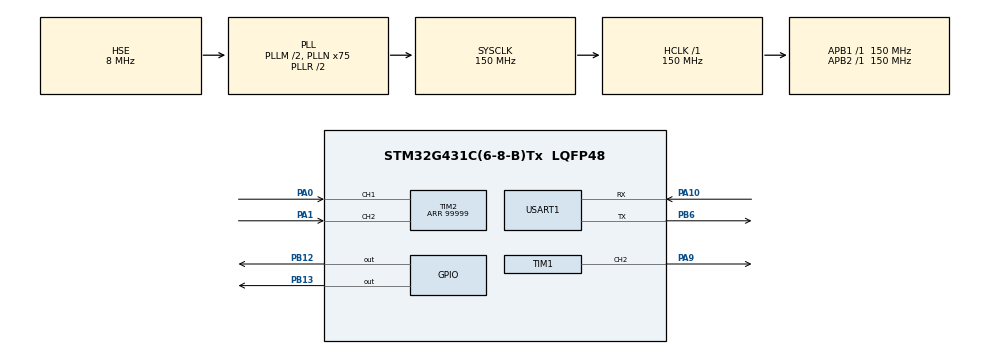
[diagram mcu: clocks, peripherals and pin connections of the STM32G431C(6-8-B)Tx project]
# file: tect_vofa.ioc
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Dma.Request0=USART1_TX
Dma.USART1_TX.0.Direction=DMA_MEMORY_TO_PERIPH
Dma.USART1_TX.0.EventEnable=DISABLE
Dma.USART1_TX.0.Instance=DMA1_Channel1
Dma.USART1_TX.0.MemDataAlignment=DMA_MDATAALIGN_BYTE
Dma.USART1_TX.0.MemInc=DMA_MINC_ENABLE
Dma.USART1_TX.0.Mode=DMA_NORMAL
Dma.USART1_TX.0.PeriphDataAlignment=DMA_PDATAALIGN_BYTE
Dma.USART1_TX.0.PeriphInc=DMA_PINC_DISABLE
Dma.USART1_TX.0.Polarity=HAL_DMAMUX_REQ_GEN_RISING
Dma.USART1_TX.0.Priority=DMA_PRIORITY_LOW
Dma.USART1_TX.0.RequestNumber=1
Dma.USART1_TX.0.SignalID=NONE
Dma.USART1_TX.0.SyncEnable=DISABLE
Dma.USART1_TX.0.SyncPolarity=HAL_DMAMUX_SYNC_NO_EVENT
Dma.USART1_TX.0.SyncRequestNumber=1
Dma.USART1_TX.0.SyncSignalID=NONE
Mcu.Family=STM32G4
Mcu.Name=STM32G431C(6-8-B)Tx
Mcu.Package=LQFP48
NVIC.DMA1_Channel1_IRQn=true\:0\:0\:false\:false\:true\:false\:true\:true
NVIC.PriorityGroup=NVIC_PRIORITYGROUP_4
NVIC.TIM6_DAC_IRQn=true\:9\:0\:true\:false\:true\:true\:true\:true
NVIC.TIM7_IRQn=true\:8\:0\:true\:false\:true\:true\:true\:true
NVIC.USART1_IRQn=true\:10\:0\:true\:false\:true\:false\:true\:true
PA0.Signal=S_TIM2_CH1
PA1.Signal=S_TIM2_CH2
PA10.Mode=Asynchronous
PA10.Signal=USART1_RX
PA13.Mode=Serial_Wire
PA13.Signal=SYS_JTMS-SWDIO
PA14.Mode=Serial_Wire
PA14.Signal=SYS_JTCK-SWCLK
PA9.Signal=S_TIM1_CH2
PB12.Signal=GPIO_Output
PB13.Signal=GPIO_Output
PB6.Mode=Asynchronous
PB6.Signal=USART1_TX
PC14-OSC32_IN.Mode=LSE-External-Oscillator
PC14-OSC32_IN.Signal=RCC_OSC32_IN
PC15-OSC32_OUT.Mode=LSE-External-Oscillator
PC15-OSC32_OUT.Signal=RCC_OSC32_OUT
PF0-OSC_IN.Mode=HSE-External-Oscillator
PF0-OSC_IN.Signal=RCC_OSC_IN
PF1-OSC_OUT.Mode=HSE-External-Oscillator
PF1-OSC_OUT.Signal=RCC_OSC_OUT
ProjectManager.HeapSize=0x200
ProjectManager.StackSize=0x400
ProjectManager.TargetToolchain=MDK-ARM V5.32
RCC.ADC12Freq_Value=150000000
RCC.AHBFreq_Value=150000000
RCC.APB1Freq_Value=150000000
RCC.APB1TimFreq_Value=150000000
RCC.APB2Freq_Value=150000000
RCC.APB2TimFreq_Value=150000000
RCC.CortexFreq_Value=150000000
RCC.EXTERNAL_CLOCK_VALUE=12288000
RCC.HCLKFreq_Value=150000000
RCC.HSE_VALUE=8000000
RCC.HSI48_VALUE=48000000
RCC.HSI_VALUE=16000000
RCC.PLLM=RCC_PLLM_DIV2
RCC.PLLN=75
RCC.PLLSourceVirtual=RCC_PLLSOURCE_HSE
RCC.SYSCLKFreq_VALUE=150000000
RCC.SYSCLKSource=RCC_SYSCLKSOURCE_PLLCLK
RCC.USBFreq_Value=150000000
RCC.VCOOutputFreq_Value=300000000
SH.S_TIM1_CH2.0=TIM1_CH2,PWM Generation2 CH2
SH.S_TIM2_CH1.0=TIM2_CH1,Encoder_Interface
SH.S_TIM2_CH2.0=TIM2_CH2,Encoder_Interface
TIM1.Channel-PWM\ Generation2\ CH2=TIM_CHANNEL_2
TIM1.PeriodNoDither=1499
TIM1.Prescaler=9
TIM2.EncoderMode=TIM_ENCODERMODE_TI12
TIM2.PeriodNoDither=99999
TIM6.PeriodNoDither=999
TIM6.Prescaler=149
TIM7.PeriodNoDither=9999
TIM7.Prescaler=149
USART1.VirtualMode-Asynchronous=VM_ASYNC
VP_SYS_VS_DBSignals.Mode=DisableDeadBatterySignals
VP_TIM6_VS_ClockSourceINT.Mode=Enable_Timer
VP_TIM7_VS_ClockSourceINT.Mode=Enable_Timer
board=custom

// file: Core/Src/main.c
/* USER CODE BEGIN Header */
/**
 ******************************************************************************
 * @file           : main.c
 * @brief          : Main program body
 ******************************************************************************
 * @attention
 *
 * Copyright (c) 2024 STMicroelectronics.
 * All rights reserved.
 *
 * This software is licensed under terms that can be found in the LICENSE file
 * in the root directory of this software component.
 * If no LICENSE file comes with this software, it is provided AS-IS.
 *
 ******************************************************************************
 */
/* USER CODE END Header */
#include "main.h"
#include "dma.h"
#include "tim.h"
#include "usart.h"
#include "gpio.h"

/* USER CODE BEGIN Includes */
//#include "vofa.h"
//#include "ps2.h"
//#include "bsp_usart.h"
#include "motor.h"
#include "Callback.h"
#include "pid.h"
/* USER CODE END Includes */

void SystemClock_Config(void);

/* USER CODE BEGIN 0 */
Motor MG513_motor;
pids pid1;
//extern PS2 ps2;
uint8_t RxData[8] = {0};
/* USER CODE END 0 */

int main(void)
{

  /* MCU Configuration--------------------------------------------------------*/

  /* Reset of all peripherals, Initializes the Flash interface and the Systick. */
  HAL_Init();

  /* Configure the system clock */
  SystemClock_Config();

  /* Initialize all configured peripherals */
  MX_GPIO_Init();
  MX_DMA_Init();
  MX_USART1_UART_Init();
  MX_TIM1_Init();
  MX_TIM2_Init();
  MX_TIM6_Init();
  MX_TIM7_Init();
  /* USER CODE BEGIN 2 */
  //__HAL_UART_ENABLE(&huart1);
  motor_pid_init(&MG513_motor,&pid1,MOTOR_SPEED, PID_POSITION, 100,1, 0, 0, 70, 200);
  motor_init();
  //HAL_UART_Receive_IT(&huart1,RxData,1);
  //PS2_SetInit();
  /* USER CODE END 2 */

  /* Infinite loop */
  /* USER CODE BEGIN WHILE */
  while (1)
  {

    // PS2_Receive();
    //printf("999\n");
    // printf("%d\n", ps2.LY);
    // printf("%d\n", ps2.RX);
    // printf("%d\n", ps2.RY);
    // printf("%d\n", ps2.KEY);
    // HAL_Delay(1000);
    /* USER CODE END WHILE */

  }
}

void SystemClock_Config(void)
{
  RCC_OscInitTypeDef RCC_OscInitStruct = {0};
  RCC_ClkInitTypeDef RCC_ClkInitStruct = {0};

  /** Configure the main internal regulator output voltage
  */
  HAL_PWREx_ControlVoltageScaling(PWR_REGULATOR_VOLTAGE_SCALE1);

  /** Initializes the RCC Oscillators according to the specified parameters
  * in the RCC_OscInitTypeDef structure.
  */
  RCC_OscInitStruct.OscillatorType = RCC_OSCILLATORTYPE_HSE;
  RCC_OscInitStruct.HSEState = RCC_HSE_ON;
  RCC_OscInitStruct.PLL.PLLState = RCC_PLL_ON;
  RCC_OscInitStruct.PLL.PLLSource = RCC_PLLSOURCE_HSE;
  RCC_OscInitStruct.PLL.PLLM = RCC_PLLM_DIV2;
  RCC_OscInitStruct.PLL.PLLN = 75;
  RCC_OscInitStruct.PLL.PLLP = RCC_PLLP_DIV2;
  RCC_OscInitStruct.PLL.PLLQ = RCC_PLLQ_DIV2;
  RCC_OscInitStruct.PLL.PLLR = RCC_PLLR_DIV2;
  if (HAL_RCC_OscConfig(&RCC_OscInitStruct) != HAL_OK)
  {
    Error_Handler();
  }

  /** Initializes the CPU, AHB and APB buses clocks
  */
  RCC_ClkInitStruct.ClockType = RCC_CLOCKTYPE_HCLK|RCC_CLOCKTYPE_SYSCLK
                              |RCC_CLOCKTYPE_PCLK1|RCC_CLOCKTYPE_PCLK2;
  RCC_ClkInitStruct.SYSCLKSource = RCC_SYSCLKSOURCE_PLLCLK;
  RCC_ClkInitStruct.AHBCLKDivider = RCC_SYSCLK_DIV1;
  RCC_ClkInitStruct.APB1CLKDivider = RCC_HCLK_DIV1;
  RCC_ClkInitStruct.APB2CLKDivider = RCC_HCLK_DIV1;

  if (HAL_RCC_ClockConfig(&RCC_ClkInitStruct, FLASH_LATENCY_4) != HAL_OK)
  {
    Error_Handler();
  }
}

void Error_Handler(void)
{
  __disable_irq();
  while (1)
  {
  }
}
